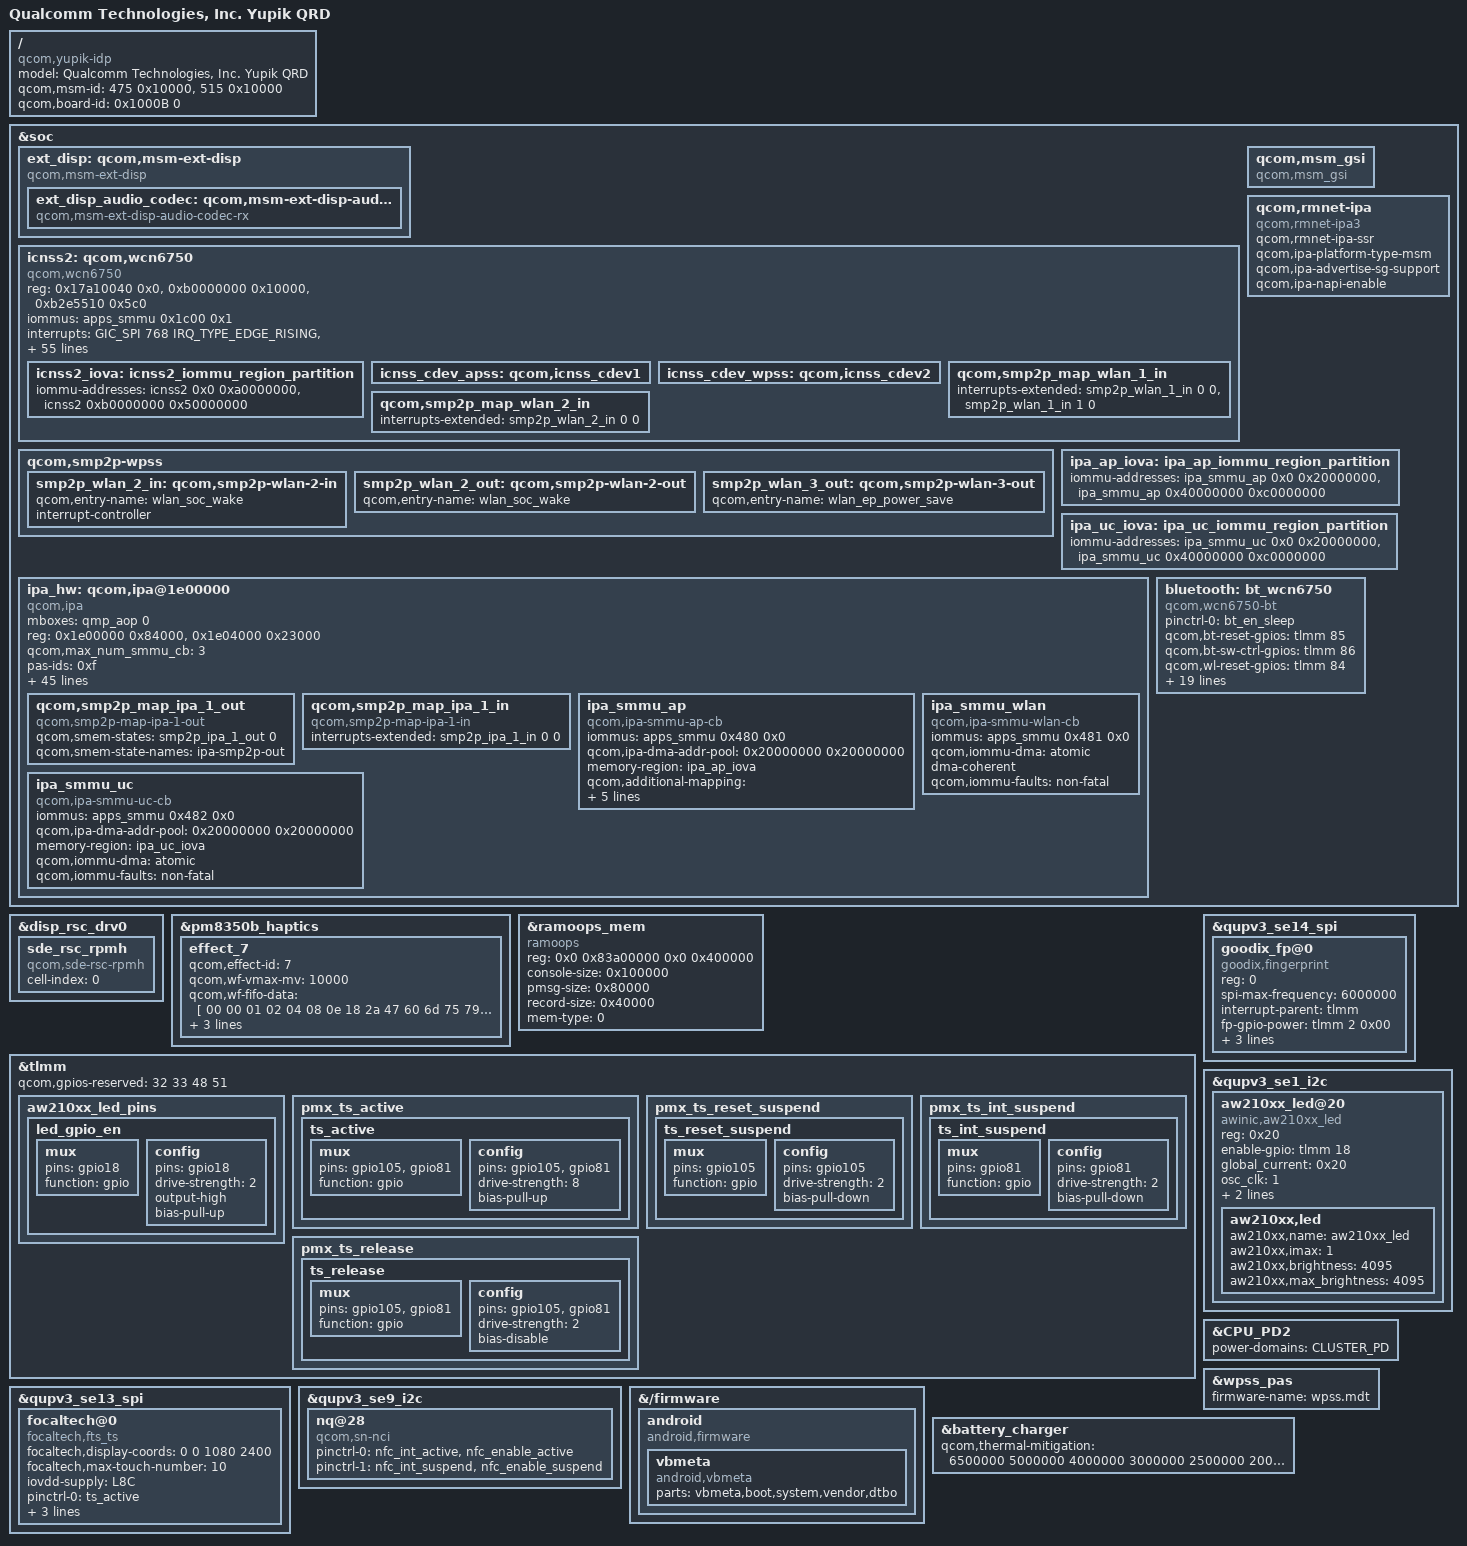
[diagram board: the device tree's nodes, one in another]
// SPDX-License-Identifier: BSD-3-Clause
/*
 * Nothing Phone (1) "Spacewar" overlay, ported from the 5.4-era NOS-5.0
 * tree onto Qualcomm's stock 6.12 yupik-qrd base.
 *
 * This is deliberately its OWN overlay, not an edit to Qualcomm's shared
 * yupik-qrd-overlay.dtso: that file is cross-combined by
 * qcom/Makefile's NOAPQ_YUPIK_BOARDS x YUPIK_BASE_DTB product against
 * yupik-iot/katmai/etc, none of which carry our board-specific nodes.
 * Wired in qcom/Makefile as its own narrow combination, paired only with
 * yupik.dtb -- same pattern as redwood's own standalone redwood-overlay.dtso.
 *
 * Board identity (model/compatible/qcom,msm-id/qcom,board-id) is left
 * identical to stock yupik-qrd-overlay.dtso: Nothing's real 5.4 firmware
 * never renamed these either -- confirmed against the shipped
 * android_kernel_nothing_sm7325 tree's own yupik-qrd.dts.
 */

/dts-v1/;
/plugin/;

/*
 * yupik-gpu.dtsi/yupik-gpu-pwrlevels.dtsi (below) target &msm_gpu, a label
 * only yupik.dtsi defines -- not pulled in automatically here since this
 * overlay is its own compilation unit (macros from yupik.dtsi's own
 * #includes don't carry over at FDT-apply time), so these five headers
 * are repeated from graphics-devicetree's own yupik-gpu.dts wrapper.
 */
#include <dt-bindings/clock/qcom,aop-qmp.h>
#include <dt-bindings/clock/qcom,gcc-sc7280.h>
#include <dt-bindings/clock/qcom,gpucc-sc7280.h>
#include <dt-bindings/clock/qcom,rpmh.h>
#include <dt-bindings/interconnect/qcom,yupik.h>
#include <dt-bindings/interrupt-controller/arm-gic.h>
#include <dt-bindings/regulator/qcom,rpmh-regulator-levels.h>

/* Display (SDE/DSI) headers -- same "own compilation unit" reason as above. */
#include <dt-bindings/clock/mdss-5nm-pll-clk.h>
#include <dt-bindings/clock/qcom,dispcc-sc7280.h>
#include <dt-bindings/gpio/gpio.h>
#include <dt-bindings/interconnect/qcom,icc.h>
#include <dt-bindings/interrupt-controller/irq.h>

/* Audio (LPASS/bolero) headers -- same "own compilation unit" reason as above. */
#include <dt-bindings/clock/qcom,audio-ext-clk.h>
#include <dt-bindings/sound/audio-codec-port-types.h>
#include <dt-bindings/sound/qcom,bolero-clk-rsc.h>

/* PM8350B haptics header (effect_7 below) -- same reason as above. */
#include <dt-bindings/input/qcom,hv-haptics.h>

#include "yupik-qrd.dtsi"
#include "yupik-abra-common-overlay.dtsi"

/*
 * GPU devicetree, from graphics-devicetree (gfx-devicetree-oss.lnx.16.0.r8-rel)
 * as-is -- Qualcomm's own release already ships yupik-gpu.dtsi/pwrlevels,
 * unlike display (see below), so no 5.4 porting needed here.
 */
#include "yupik-gpu.dtsi"
#include "yupik-gpu-pwrlevels.dtsi"

/*
 * Display: genuinely ported from the 5.4-era tree, not a stock-as-is
 * include like GPU above -- Qualcomm's 6.12 yupik release ships zero
 * display nodes at all. Core SDE/DSI binding + pinctrl are chip-generic
 * (reused from redwood's own port); the panel and its wiring below are
 * Spacewar's actual Visionox RM692E5, carried over from the 5.4 tree.
 */
#include "display/yupik-spacewar-sde-pinctrl.dtsi"
#include "display/yupik-spacewar-sde.dtsi"
#include "display/yupik-spacewar-sde-display.dtsi"

/*
 * Camera: same "Qualcomm's 6.12 release ships none of this for yupik"
 * gap as display above. Platform core (CCI/CSIPHY/Titan/SMMU) from
 * redwood's own yupik port, confirmed chip-generic; Spacewar's real
 * sensors (FocalTech-class rear wide/ultrawide + front, from the 5.4
 * tree's abra-camera-sensor.dtsi) in the second file.
 */
#include "camera/yupik-spacewar-camera.dtsi"
#include "camera/yupik-spacewar-camera-sensor.dtsi"

/*
 * Audio, missing from stock 6.12 like display/camera above. LPASS/sound-card
 * skeleton from redwood; codec/SWR-bus detail from the 5.4 tree; the real
 * board config (nothing-spacewar-audio-overlay.dtsi) from Willay24's tree.
 * msm-audio-lpass.dtsi isn't included here -- yupik-audio.dtsi already does.
 */
#include "yupik-audio.dtsi"
#include "yupik-audio-overlay.dtsi"
#include "nothing-spacewar-audio-overlay.dtsi"

/* Venus video decoder/encoder (msm_vidc) */
#include "yupik-spacewar-video.dtsi"

/* External-display (USB-C DP/HDMI) audio passthrough codec, missing from stock 6.12. */
&soc {
	ext_disp: qcom,msm-ext-disp {
		compatible = "qcom,msm-ext-disp";

		ext_disp_audio_codec: qcom,msm-ext-disp-audio-codec-rx {
			compatible = "qcom,msm-ext-disp-audio-codec-rx";
		};
	};
};

/*
 * The display driver finds its RPMh device through this node; stock 6.12 yupik.dtsi lacks it.
 * It must sit under drv@0: rpmh_*() read the controller from the parent's drvdata.
 */
&disp_rsc_drv0 {
	sde_rsc_rpmh {
		compatible = "qcom,sde-rsc-rpmh";
		cell-index = <0>;
	};
};

/* PM8350B effect_7 waveform, missing from stock 6.12 pm8350b.dtsi. */
&pm8350b_haptics {
	effect_7 {
		/* FIFO sample only */
		qcom,effect-id = <7>;
		qcom,wf-vmax-mv = <10000>;
		qcom,wf-fifo-data = [
					00 00 01 02 04 08 0e 18
					2a 47 60 6d 75 79 7c 7d
					7e 7d 7d 7b 77 71 66 53
					33 fb c7 a9 98 8e 88 85
					83 82 81 81 81 82 83 84
					87 8d 96 a6 c1 f2 22 36
					35 1b e8 bb a3 94 8c 87
					84 82 82 81 81 81 81 81
					81 82 83 85 88 8e 97 a8
					c5 f8 2e 4c 5e 67 6a 69
					62 53 39 21 13 0b 06 03
					02 01 00  ];
		qcom,wf-fifo-period = <S_PERIOD_F_8KHZ>;
		qcom,wf-brake-disable;
		qcom,wf-auto-res-disable;
	};
};

/ {
	model = "Qualcomm Technologies, Inc. Yupik QRD";
	compatible = "qcom,yupik-idp", "qcom,yupik", "qcom,qrd";
	qcom,msm-id = <475 0x10000>, <515 0x10000>;
	qcom,board-id = <0x1000B 0>;
};

/* Static ramoops at the stock address/layout; write-combine (not cached, unaligned-safe). */
&ramoops_mem {
	compatible = "ramoops";
	reg = <0x0 0x83a00000 0x0 0x400000>;
	console-size = <0x100000>;
	pmsg-size = <0x80000>;
	record-size = <0x40000>;	/* panic/oops dmesg: full trace */
	mem-type = <0>;
};

/*
 * Nothing Glyph interface (AW210xx LED driver), ported from the 5.4-era
 * yupik-qrd.dtsi. qupv3_se1_i2c and the gpio18 enable line are the same
 * controller/pin on this base (confirmed against yupik-qupv3.dtsi: both
 * 5.4 and 6.12 define qupv3_se1_i2c as i2c@984000) -- not board-renumbered,
 * so this is ported as-is, not guessed.
 */
&tlmm {
	/* Camera needs GPIO 49/50, so drop them from the reserved list. */
	qcom,gpios-reserved = <32 33 48 51>;

	aw210xx_led_pins {
		led_gpio_en: led_gpio_en {
			mux {
				pins = "gpio18";
				function = "gpio";
			};

			config {
				pins = "gpio18";
				drive-strength = <2>;
				output-high;
				bias-pull-up;
			};
		};
	};

	/*
	 * FocalTech touch reset/irq pinctrl states, ported as-is from the
	 * 5.4-era yupik-pinctrl.dtsi -- same gpio105 (reset)/gpio81 (irq)
	 * pins on this base (confirmed against yupik-qupv3.dtsi: both 5.4
	 * and 6.12 wire qupv3_se13_spi to the same SE/pins).
	 */
	pmx_ts_active {
		ts_active: ts_active {
			mux {
				pins = "gpio105", "gpio81";
				function = "gpio";
			};

			config {
				pins = "gpio105", "gpio81";
				drive-strength = <8>;
				bias-pull-up;
			};
		};
	};

	pmx_ts_reset_suspend {
		ts_reset_suspend: ts_reset_suspend {
			mux {
				pins = "gpio105";
				function = "gpio";
			};

			config {
				pins = "gpio105";
				drive-strength = <2>;
				bias-pull-down;
			};
		};
	};

	pmx_ts_int_suspend {
		ts_int_suspend: ts_int_suspend {
			mux {
				pins = "gpio81";
				function = "gpio";
			};

			config {
				pins = "gpio81";
				drive-strength = <2>;
				bias-pull-down;
			};
		};
	};

	pmx_ts_release {
		ts_release: ts_release {
			mux {
				pins = "gpio105", "gpio81";
				function = "gpio";
			};

			config {
				pins = "gpio105", "gpio81";
				drive-strength = <2>;
				bias-disable;
			};
		};
	};
};

/*
 * FocalTech touch (focaltech,fts_ts), ported from the 5.4-era
 * yupik-qrd.dtsi. Qualcomm's own stock 6.12 yupik-qrd.dtsi already
 * carries a focaltech@0 node under qupv3_se13_spi (same SPI bus/IRQ/
 * reset-gpio, confirmed identical) -- it's missing "compatible" and the
 * pinctrl/iovdd/panel wiring, and its touch-coords/max-touch-number are
 * generic-QRD values, not Spacewar's real Visionox panel numbers. This
 * overlay fragment only adds/overrides what's missing; everything else
 * (bus, reg, interrupts, reset/irq gpio, vdd-supply, trusted-touch-*)
 * already comes from the stock node.
 *
 * The 5.4-era tree also carries a goodix-berlin@0 node at this exact
 * same bus/reg, gated by a sibling "qcom,spi-touch-active" string on
 * qupv3_se13_spi itself. On the shipped Spacewar tree that string is
 * "focaltech,fts_ts" -- Goodix Berlin is present only as an alternate
 * touch-IC sourcing option for this same physical touch digitizer, never
 * the active device, so it's deliberately not ported here. (Not a
 * second touch position, and not tied to a different panel -- both
 * candidate nodes carry the identical panel phandle below.) Stock
 * already sets qcom,spi-touch-active to "focaltech,fts_ts" on this bus,
 * so no override is needed here either.
 */
&qupv3_se13_spi {
	focaltech@0 {
		compatible = "focaltech,fts_ts";
		focaltech,display-coords = <0 0 1080 2400>;
		focaltech,max-touch-number = <10>;
		iovdd-supply = <&L8C>;
		pinctrl-names = "pmx_ts_active", "pmx_ts_suspend", "pmx_ts_release";
		pinctrl-0 = <&ts_active>;
		pinctrl-1 = <&ts_int_suspend &ts_reset_suspend>;
		pinctrl-2 = <&ts_release>;
		panel = <&dsi_rm692e5_visionox_amoled_120hz_cmd>;
	};
};

/*
 * NFC (qcom,sn-nci / nfc_i2c_drv.c), ported from the 5.4-era
 * yupik-qrd.dtsi. Stock 6.12 yupik-qrd.dtsi already carries an identical
 * nq@28 node on qupv3_se9_i2c (same reg/irq/supply/gpio wiring,
 * confirmed line-for-line against the 5.4 tree) -- it's missing
 * "compatible" and never wires pinctrl-0/1 to real phandles, even though
 * yupik-pinctrl.dtsi already defines nfc_int_active/nfc_enable_active at
 * the same gpio38/39/40/41 pins the stock node itself references. Same
 * shape as the touch fragment above: only what's missing is added.
 */
&qupv3_se9_i2c {
	nq@28 {
		compatible = "qcom,sn-nci";
		pinctrl-0 = <&nfc_int_active &nfc_enable_active>;
		pinctrl-1 = <&nfc_int_suspend &nfc_enable_suspend>;
	};
};

/*
 * Goodix fingerprint/UDFPS (gf_spi, goodix,fingerprint) -- a separate
 * chip from the touch controller above, on its own SPI bus
 * (qupv3_se14_spi). Ported from the 5.4-era yupik-qrd.dtsi; unlike
 * touch, Qualcomm's stock 6.12 yupik-qrd.dtsi has no fingerprint node
 * at all here (the qupv3_se14_spi controller exists, disabled, with no
 * child device), so this is added fresh rather than overridden. The
 * driver resolves its own IRQ from fp-gpio-irq at runtime
 * (gpio_to_irq()), so no devicetree "interrupts" property is needed,
 * matching the 5.4 node.
 */
&qupv3_se14_spi {
	status = "ok";
	goodix_fp@0 {
		compatible = "goodix,fingerprint";
		reg = <0>;
		spi-max-frequency = <6000000>;
		interrupt-parent = <&tlmm>;
		fp-gpio-power = <&tlmm 2 0x00>;
		fp-gpio-irq = <&tlmm 34 0x00>;
		fp-gpio-reset = <&tlmm 61 0x00>;
		panel = <&dsi_rm692e5_visionox_amoled_120hz_cmd>;
		status = "okay";
	};
};

&qupv3_se1_i2c {
	status = "ok";
	aw210xx_led@20 {
		compatible = "awinic,aw210xx_led";
		reg = <0x20>;
		enable-gpio = <&tlmm 18 0x00>;
		global_current = <0x20>;
		osc_clk = <1>;
		br_res = <3>;
		pinctrl-names = "default";
		pinctrl-0 = <&led_gpio_en>;
		status = "ok";
		aw210xx,led {
			aw210xx,name = "aw210xx_led";
			aw210xx,imax = <1>;
			aw210xx,brightness = <4095>;
			aw210xx,max_brightness = <4095>;
		};
	};
};

/* First-stage init reads these to create the vbmeta/boot/dtbo by-name nodes. */
&{/firmware} {
	android {
		compatible = "android,firmware";
		vbmeta {
			compatible = "android,vbmeta";
			parts = "vbmeta,boot,system,vendor,dtbo";
		};
	};
};

/* yupik.dtsi spells CPU_PD2's property "Power-domains", so cpu2 never joined the cluster domain. */
&CPU_PD2 {
	power-domains = <&CLUSTER_PD>;
};

/* Legacy FastRPC: the vendor libadsprpc needs the 5.4 ioctl ABI (frpc-adsprpc). */
#include "yupik-spacewar-fastrpc.dtsi"

/* WCN6750 Wi-Fi: 6.12 yupik.dtsi lacks the icnss2 node (ported from 5.4). */
&soc {
	icnss2: qcom,wcn6750 {
		compatible = "qcom,wcn6750";
		reg = <0x17a10040 0x0>,
		      <0xb0000000 0x10000>,
		      <0xb2e5510 0x5c0>;
		reg-names = "msi_addr", "smmu_iova_ipa", "tcs_cmd";
		iommus = <&apps_smmu 0x1c00 0x1>;
		interrupts = <GIC_SPI 768 IRQ_TYPE_EDGE_RISING>,
			     <GIC_SPI 769 IRQ_TYPE_EDGE_RISING>,
			     <GIC_SPI 770 IRQ_TYPE_EDGE_RISING>,
			     <GIC_SPI 771 IRQ_TYPE_EDGE_RISING>,
			     <GIC_SPI 772 IRQ_TYPE_EDGE_RISING>,
			     <GIC_SPI 773 IRQ_TYPE_EDGE_RISING>,
			     <GIC_SPI 774 IRQ_TYPE_EDGE_RISING>,
			     <GIC_SPI 775 IRQ_TYPE_EDGE_RISING>,
			     <GIC_SPI 776 IRQ_TYPE_EDGE_RISING>,
			     <GIC_SPI 777 IRQ_TYPE_EDGE_RISING>,
			     <GIC_SPI 778 IRQ_TYPE_EDGE_RISING>,
			     <GIC_SPI 779 IRQ_TYPE_EDGE_RISING>,
			     <GIC_SPI 780 IRQ_TYPE_EDGE_RISING>,
			     <GIC_SPI 781 IRQ_TYPE_EDGE_RISING>,
			     <GIC_SPI 782 IRQ_TYPE_EDGE_RISING>,
			     <GIC_SPI 783 IRQ_TYPE_EDGE_RISING>,
			     <GIC_SPI 784 IRQ_TYPE_EDGE_RISING>,
			     <GIC_SPI 785 IRQ_TYPE_EDGE_RISING>,
			     <GIC_SPI 786 IRQ_TYPE_EDGE_RISING>,
			     <GIC_SPI 787 IRQ_TYPE_EDGE_RISING>,
			     <GIC_SPI 788 IRQ_TYPE_EDGE_RISING>,
			     <GIC_SPI 789 IRQ_TYPE_EDGE_RISING>,
			     <GIC_SPI 790 IRQ_TYPE_EDGE_RISING>,
			     <GIC_SPI 791 IRQ_TYPE_EDGE_RISING>,
			     <GIC_SPI 792 IRQ_TYPE_EDGE_RISING>,
			     <GIC_SPI 793 IRQ_TYPE_EDGE_RISING>,
			     <GIC_SPI 794 IRQ_TYPE_EDGE_RISING>,
			     <GIC_SPI 795 IRQ_TYPE_EDGE_RISING>,
			     <GIC_SPI 796 IRQ_TYPE_EDGE_RISING>,
			     <GIC_SPI 797 IRQ_TYPE_EDGE_RISING>,
			     <GIC_SPI 798 IRQ_TYPE_EDGE_RISING>,
			     <GIC_SPI 799 IRQ_TYPE_EDGE_RISING>;

		qcom,iommu-dma = "fastmap";
		qcom,iommu-faults = "stall-disable", "HUPCF", "non-fatal";
		memory-region = <&icnss2_iova>;
		qcom,iommu-geometry = <0xa0000000 0x10010000>;
		qcom,wlan-msa-fixed-region = <&wlan_fw_mem>;
		qcom,rproc-handle = <&wpss_pas>;
		/* The modem image is 5.4-era: it never answers the newer soc-wake smp2p. */
		qcom,wlan-legacy-ipc-transport;
		qcom,cmd_db_name = "smpb7";
		cnss-daemon-support;
		dma-coherent;
		qcom,fw-prefix;
		qcom,wlan;
		vdd-cx-mx-supply = <&S7B>;
		qcom,vdd-cx-mx-config = <824000 1120000 0 0 1>;
		vdd-1.8-xo-supply = <&S1B>;
		qcom,vdd-1.8-xo-config = <1872000 2040000 0 0 0>;
		vdd-1.3-rfa-supply = <&S8B>;
		qcom,vdd-1.3-rfa-config = <1256000 1500000 0 0 0>;
		qcom,smem-states = <&smp2p_wlan_1_out 0>,
				   <&smp2p_wlan_2_out 0>,
				   <&smp2p_wlan_3_out 0>;
		qcom,smem-state-names = "wlan-smp2p-out",
					"wlan-soc-wake-smp2p-out",
					"wlan-ep-powersave-smp2p-out";

		/* 6.12 dropped qcom,iommu-dma-addr-pool: reserve around the 256M window at 0xa0000000. */
		icnss2_iova: icnss2_iommu_region_partition {
			iommu-addresses = <&icnss2 0x0 0xa0000000>,
					  <&icnss2 0xb0000000 0x50000000>;
		};

		icnss_cdev_apss: qcom,icnss_cdev1 {
			#cooling-cells = <2>;
		};

		icnss_cdev_wpss: qcom,icnss_cdev2 {
			#cooling-cells = <2>;
		};

		qcom,smp2p_map_wlan_1_in {
			interrupts-extended = <&smp2p_wlan_1_in 0 0>,
					      <&smp2p_wlan_1_in 1 0>;
			interrupt-names = "qcom,smp2p-force-fatal-error",
					  "qcom,smp2p-early-crash-ind";
		};

		qcom,smp2p_map_wlan_2_in {
			interrupts-extended = <&smp2p_wlan_2_in 0 0>;
			interrupt-names = "qcom,smp2p-soc-wake-ack";
		};
	};
};

/* soc-wake / endpoint-powersave smp2p entries the 6.12 icnss2 asks for. */
&soc {
	qcom,smp2p-wpss {
		smp2p_wlan_2_in: qcom,smp2p-wlan-2-in {
			qcom,entry-name = "wlan_soc_wake";
			interrupt-controller;
			#interrupt-cells = <2>;
		};

		smp2p_wlan_2_out: qcom,smp2p-wlan-2-out {
			qcom,entry-name = "wlan_soc_wake";
			#qcom,smem-state-cells = <1>;
		};

		smp2p_wlan_3_out: qcom,smp2p-wlan-3-out {
			qcom,entry-name = "wlan_ep_power_save";
			#qcom,smem-state-cells = <1>;
		};
	};
};

/* The modem partition keeps the WPSS image at image/wpss.*, not image/qca6750/. */
&wpss_pas {
	firmware-name = "wpss.mdt";
};

/* IPA v4.11 for USB (usb_f_gsi) and mobile data, ported from 5.4 and redwood's 6.12 IPA node; 6.12 yupik.dtsi has none. */
&soc {
	qcom,msm_gsi {
		compatible = "qcom,msm_gsi";
	};

	qcom,rmnet-ipa {
		compatible = "qcom,rmnet-ipa3";
		qcom,rmnet-ipa-ssr;
		qcom,ipa-platform-type-msm;
		qcom,ipa-advertise-sg-support;
		qcom,ipa-napi-enable;
	};

	/*
	 * 6.12 dropped qcom,iommu-dma-addr-pool, and without an IOVA window
	 * the AP and uC context banks get no IOMMU domain. Reserve everything
	 * below 4G around the 512M window at 0x20000000 the 5.4 pool gave them;
	 * the driver reads the window itself from qcom,ipa-dma-addr-pool.
	 * The entries take the 1/1 cells of soc. Written with 64-bit cells,
	 * they parsed into a lone reservation of [0, 1G): IPA then took DMA
	 * IOVAs above 1G, one replaced the 1:1 map of the modem filter table
	 * in SMEM, IPA faulted reading it and the modem asserted.
	 */
	ipa_ap_iova: ipa_ap_iommu_region_partition {
		iommu-addresses = <&ipa_smmu_ap 0x0 0x20000000>,
				  <&ipa_smmu_ap 0x40000000 0xc0000000>;
	};

	ipa_uc_iova: ipa_uc_iommu_region_partition {
		iommu-addresses = <&ipa_smmu_uc 0x0 0x20000000>,
				  <&ipa_smmu_uc 0x40000000 0xc0000000>;
	};

	ipa_hw: qcom,ipa@1e00000 {
		compatible = "qcom,ipa";
		mboxes = <&qmp_aop 0>;
		reg =
			<0x1e00000 0x84000>,
			<0x1e04000 0x23000>;
		reg-names = "ipa-base", "gsi-base";
		qcom,max_num_smmu_cb = <3>;
		pas-ids = <0xf>;
		firmware-names = "yupik_ipa_fws";
		memory-regions = <&pil_ipa_gsi_mem>;
		interrupts =
			<0 654 IRQ_TYPE_LEVEL_HIGH>,
			<0 432 IRQ_TYPE_LEVEL_HIGH>;
		interrupt-names = "ipa-irq", "gsi-irq";
		qcom,ipa-hw-ver = <20>; /* IPA core version = IPAv4.11 */
		qcom,ipa-hw-mode = <0>;
		qcom,platform-type = <1>; /* MSM platform */
		qcom,ee = <0>;
		qcom,use-ipa-tethering-bridge;
		qcom,modem-cfg-emb-pipe-flt;
		qcom,ipa-wdi3-over-gsi;
		qcom,arm-smmu;
		qcom,smmu-fast-map;
		qcom,use-64-bit-dma-mask;
		qcom,ipa-endp-delay-wa-v2;
		qcom,eth-bridging-not-supported;
		qcom,bw-monitor-supported;
		qcom,lan-rx-napi;
		qcom,tx-napi;
		/* downlink pages go to the stack without a copy */
		qcom,wan-use-skb-page;
		qcom,rmnet-ctl-enable;
		qcom,use-gsi-ipa-fw = "yupik_ipa_fws";
		qcom,tx-wrapper-cache-max-size = <400>;
		qcom,ipa-gpi-event-rp-ddr;
		clock-names = "core_clk";
		clocks = <&rpmhcc RPMH_IPA_CLK>;
		qcom,interconnect,num-cases = <5>;
		qcom,interconnect,num-paths = <3>;
		interconnects = <&aggre2_noc MASTER_IPA &gem_noc SLAVE_LLCC>,
			<&mc_virt MASTER_LLCC &mc_virt SLAVE_EBI1>,
			<&gem_noc MASTER_APPSS_PROC &cnoc2 SLAVE_IPA_CFG>;
		interconnect-names = "ipa_to_llcc", "llcc_to_ebi1", "appss_to_ipa";
		/* No vote */
		qcom,no-vote =
		<0 0 0 0 0 0>;

		/* SVS2 */
		qcom,svs2 =
		<150000 600000 150000 1804000 0 74000>;

		/* SVS */
		qcom,svs =
		<625000 1200000 625000 3072000 0 150000>;

		/* NOMINAL */
		qcom,nominal =
		<1250000 2400000 1250000 6220800 0 400000>;

		/* TURBO */
		qcom,turbo =
		<2000000 3500000 2000000 7219200 0 400000>;

		qcom,bus-vector-names = "MIN", "SVS2", "SVS", "NOMINAL",
			"TURBO";
		qcom,throughput-threshold = <600 2500 5000>;
		qcom,scaling-exceptions = <>;

		/* smp2p information */
		qcom,smp2p_map_ipa_1_out {
			compatible = "qcom,smp2p-map-ipa-1-out";
			qcom,smem-states = <&smp2p_ipa_1_out 0>;
			qcom,smem-state-names = "ipa-smp2p-out";
		};

		qcom,smp2p_map_ipa_1_in {
			compatible = "qcom,smp2p-map-ipa-1-in";
			interrupts-extended = <&smp2p_ipa_1_in 0 0>;
			interrupt-names = "ipa-smp2p-in";
		};

		ipa_smmu_ap: ipa_smmu_ap {
			compatible = "qcom,ipa-smmu-ap-cb";
			iommus = <&apps_smmu 0x480 0x0>;
			qcom,ipa-dma-addr-pool = <0x20000000 0x20000000>;
			memory-region = <&ipa_ap_iova>;
			qcom,additional-mapping =
				/* modem tables in IMEM */
				<0x146A8000 0x146A8000 0x2000>;
			dma-coherent;
			qcom,iommu-dma = "fastmap";
			qcom,ipa-q6-smem-size = <36864>;
			/*
			 * IPA registers no fault handler, so a fatal fault here is
			 * a BUG() in arm-smmu: a panic and an instant reset with
			 * no log. Log the fault and abort the access instead.
			 */
			qcom,iommu-faults = "non-fatal";
		};

		ipa_smmu_wlan: ipa_smmu_wlan {
			compatible = "qcom,ipa-smmu-wlan-cb";
			iommus = <&apps_smmu 0x481 0x0>;
			qcom,iommu-dma = "atomic";
			dma-coherent;
			qcom,iommu-faults = "non-fatal";
		};

		ipa_smmu_uc: ipa_smmu_uc {
			compatible = "qcom,ipa-smmu-uc-cb";
			iommus = <&apps_smmu 0x482 0x0>;
			qcom,ipa-dma-addr-pool = <0x20000000 0x20000000>;
			memory-region = <&ipa_uc_iova>;
			qcom,iommu-dma = "atomic";
			qcom,iommu-faults = "non-fatal";
		};

	};
};

&soc {
	bluetooth: bt_wcn6750 {
		compatible = "qcom,wcn6750-bt";
		pinctrl-names = "default";
		pinctrl-0 = <&bt_en_sleep>;
		qcom,bt-reset-gpios = <&tlmm 85 0>;
		qcom,bt-sw-ctrl-gpios = <&tlmm 86 0>;
		qcom,wl-reset-gpios = <&tlmm 84 0>;

		qcom,bt-vdd-io-supply = <&L19B>;
		qcom,bt-vdd-aon-supply = <&S7B>;
		qcom,bt-vdd-dig-supply = <&S7B>;
		qcom,bt-vdd-rfacmn-supply = <&S7B>;
		qcom,bt-vdd-rfa-0p8-supply = <&S7B>;
		qcom,bt-vdd-rfa1-supply = <&S1B>;
		qcom,bt-vdd-rfa2-supply = <&S8B>;
		qcom,bt-vdd-ipa-2p2-supply = <&S1C>;
		qcom,bt-vdd-asd-supply = <&L11C>;

		qcom,bt-vdd-io-config = <1800000 2000000 0 1>;
		qcom,bt-vdd-aon-config = <824000 1120000 0 1>;
		qcom,bt-vdd-dig-config = <824000 1120000 0 1>;
		qcom,bt-vdd-rfacmn-config = <824000 1120000 0 1>;
		qcom,bt-vdd-rfa-0p8-config = <824000 1120000 0 1>;
		qcom,bt-vdd-rfa1-config = <1872000 2040000 0 1>;
		qcom,bt-vdd-rfa2-config = <1256000 1500000 0 1>;
		qcom,bt-vdd-ipa-2p2-config = <2200000 2210000 0 1>;
		qcom,bt-vdd-asd-config = <2800000 3544000 0 1>;
	};
};

&battery_charger {
	/* FCC steps from Nothing's stock yupik-qrd */
	qcom,thermal-mitigation = <6500000 5000000 4000000 3000000 2500000
				   2000000 0>;
};
